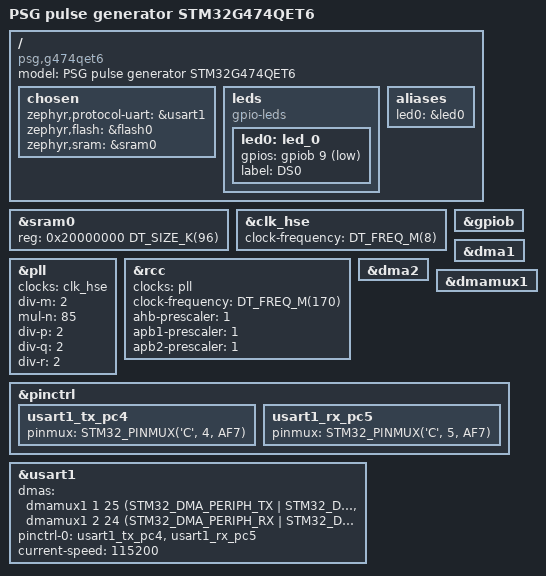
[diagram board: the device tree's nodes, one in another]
/*
 * SPDX-License-Identifier: Apache-2.0
 *
 * PSG pulse generator board, STM32G474QET6 (LQFP128).
 * Only the nodes used by the bare-metal port are enabled; everything else
 * stays disabled as defined by the upstream SoC dtsi. Pin assignments come
 * from docs/MCU外设与引脚配置.md - that table is the single source of truth.
 */

/dts-v1/;

#include <st/g4/stm32g474Xe.dtsi>
#include <zephyr/dt-bindings/gpio/gpio.h>
#include <zephyr/dt-bindings/pinctrl/stm32-pinctrl.h>
#include <zephyr/dt-bindings/dma/stm32_dma.h>

/ {
	model = "PSG pulse generator STM32G474QET6";
	compatible = "psg,g474qet6", "st,stm32g474";

	chosen {
		/*
		 * There is no console: logs leave the MCU over SEGGER RTT, so the
		 * only UART on this board belongs to the application. USART1 is
		 * named here so the firmware never has to spell out the port.
		 */
		zephyr,protocol-uart = &usart1;
		zephyr,flash = &flash0;
		zephyr,sram = &sram0;
	};

	leds: leds {
		compatible = "gpio-leds";

		led0: led_0 {
			gpios = <&gpiob 9 GPIO_ACTIVE_LOW>;
			label = "DS0";
		};
	};

	aliases {
		led0 = &led0;
	};
};

/* The linker keeps RW/ZI inside SRAM1+SRAM2 only; CCM is not used yet. */
&sram0 {
	reg = <0x20000000 DT_SIZE_K(96)>;
};

&clk_hse {
	status = "okay";
	clock-frequency = <DT_FREQ_M(8)>;
};

/* 8 MHz / 2 * 85 / 2 = 170 MHz */
&pll {
	clocks = <&clk_hse>;
	div-m = <2>;
	mul-n = <85>;
	div-p = <2>;
	div-q = <2>;
	div-r = <2>;
	status = "okay";
};

&rcc {
	clocks = <&pll>;
	clock-frequency = <DT_FREQ_M(170)>;
	ahb-prescaler = <1>;
	apb1-prescaler = <1>;
	apb2-prescaler = <1>;
};

&gpiob {
	status = "okay";
};

&dma1 {
	status = "okay";
};

/* DMAMUX1 feeds DMA1 channels 0-7 and DMA2 channels 8-15. */
&dma2 {
	status = "okay";
};

&dmamux1 {
	status = "okay";
};

&pinctrl {
	usart1_tx_pc4: usart1_tx_pc4 {
		pinmux = <STM32_PINMUX('C', 4, AF7)>;
	};

	usart1_rx_pc5: usart1_rx_pc5 {
		pinmux = <STM32_PINMUX('C', 5, AF7)>;
	};
};

/* USART1 TX is DMAMUX request 25, RX request 24; DMA1 channels are free. */
&usart1 {
	dmas = <&dmamux1 1 25 (STM32_DMA_PERIPH_TX | STM32_DMA_PRIORITY_HIGH)>,
	       <&dmamux1 2 24 (STM32_DMA_PERIPH_RX | STM32_DMA_PRIORITY_HIGH)>;
	dma-names = "tx", "rx";
	pinctrl-0 = <&usart1_tx_pc4 &usart1_rx_pc5>;
	pinctrl-names = "default";
	current-speed = <115200>;
	status = "okay";
};
